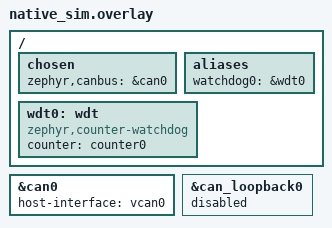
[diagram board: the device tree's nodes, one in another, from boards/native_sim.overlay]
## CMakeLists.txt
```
# Zephyr application: one codebase, two ECU roles (Kconfig choice APP_ROLE).
# Built as a freestanding application against the west workspace baked into the
# dev container (ZEPHYR_BASE).
cmake_minimum_required(VERSION 3.20.0)

# The dev image bakes firmware/west.yml into its west workspace at image build
# time, so an edited manifest changes nothing until the image is rebuilt. Make
# that mistake loud instead of silent.
if(DEFINED ENV{ZEPHYR_WORKSPACE} AND EXISTS "$ENV{ZEPHYR_WORKSPACE}/manifest/west.yml")
    file(READ "$ENV{ZEPHYR_WORKSPACE}/manifest/west.yml" baked_manifest)
    file(READ "${CMAKE_CURRENT_LIST_DIR}/../west.yml" repo_manifest)
    if(NOT baked_manifest STREQUAL repo_manifest)
        message(FATAL_ERROR
            "firmware/west.yml differs from the manifest baked into the dev image; "
            "rebuild the image with: tools/dev.sh --build")
    endif()
endif()

find_package(Zephyr REQUIRED HINTS $ENV{ZEPHYR_BASE})
project(can_ecu LANGUAGES C CXX)

target_sources(app PRIVATE
    src/main.cpp
    src/app/ecu.cpp
    src/app/test_control.cpp
    src/hal/can_bus.cpp
    src/hal/watchdog.cpp
    src/shell_cmds.c
    src/alloc_guard.c
)
target_sources_ifdef(CONFIG_APP_ROLE_SENSOR app PRIVATE src/app/sensor_role.cpp)
target_sources_ifdef(CONFIG_APP_ROLE_CONTROLLER app PRIVATE src/app/controller_role.cpp)

# No dynamic allocation after initialisation: route the public kernel and libc
# allocator entry points and the sys_heap leaf functions through
# src/alloc_guard.c, which panics once the application is up. The host C library
# is left alone on native_sim (the simulator runtime itself uses it). Symbols
# that are not compiled into the image are harmless to wrap (--gc-sections drops
# the unreferenced wrapper).
set(alloc_wrapped_symbols
    k_heap_alloc k_heap_aligned_alloc k_heap_calloc k_heap_realloc
    k_malloc k_calloc k_realloc k_aligned_alloc
    sys_heap_alloc sys_heap_aligned_alloc sys_heap_noalign_alloc sys_heap_realloc sys_heap_aligned_realloc)
if(NOT CONFIG_NATIVE_BUILD)
    list(APPEND alloc_wrapped_symbols malloc calloc realloc)
endif()
foreach(sym ${alloc_wrapped_symbols})
    zephyr_ld_options(-Wl,--wrap=${sym})
endforeach()

# Line coverage of the application under the system test suite (Phase 5):
# instrument only the application objects with gcov, not the kernel and the
# drivers (CONFIG_COVERAGE would instrument everything: 125 data files written
# at every exit, seconds on a bind-mounted checkout, and data lost whenever a
# test harness kills a process that is still writing). The flags are the ones
# Zephyr's own coverage support uses; libgcov reaches the final executable
# through the native simulator's link options, as with CONFIG_COVERAGE.
# Built by tools/build-ecu.sh native_sim <role> --coverage into build/<...>_cov/.
option(CAN_ECU_APP_COVERAGE "Instrument the application sources with gcov (native_sim only)" OFF)
if(CAN_ECU_APP_COVERAGE)
    if(NOT CONFIG_NATIVE_BUILD)
        message(FATAL_ERROR "CAN_ECU_APP_COVERAGE needs a native_sim build (the host's gcov)")
    endif()
    target_compile_options(app PRIVATE $<TARGET_PROPERTY:compiler,coverage>)
    target_link_options(native_simulator INTERFACE $<TARGET_PROPERTY:linker,coverage>)
endif()

# Platform-independent libraries (header-only): the generated protocol codec and
# the ECU state machines, both unit tested on the host (firmware/lib).
target_include_directories(app PRIVATE
    src
    ${CMAKE_CURRENT_SOURCE_DIR}/../lib/protocol/include
    ${CMAKE_CURRENT_SOURCE_DIR}/../lib/ecu_core/include
)
```

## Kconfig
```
# Application configuration. Select on the west command line, e.g.
#   west build -b native_sim -s firmware/app -- -DCONFIG_APP_ROLE_CONTROLLER=y
# or interactively with `west build -t menuconfig`.
mainmenu "can-ecu-sim firmware"

choice APP_ROLE
	prompt "ECU role"
	default APP_ROLE_SENSOR
	help
	  One codebase builds both nodes of the network. The role selects which
	  messages are published, which are monitored, and the node policy
	  (the controller has a safe state, the sensor only degrades).

config APP_ROLE_SENSOR
	bool "Sensor ECU: publishes SENSOR_DATA, BATTERY_STATUS and its heartbeat"

config APP_ROLE_CONTROLLER
	bool "Controller ECU: consumes sensor data, publishes CONTROLLER_COMMAND, has a safe state"

endchoice

config APP_TEST_HOOKS
	bool "Test-only hooks: accept TEST_CONTROL, simulate CAN controller error states"
	default y if BOARD_NATIVE_SIM
	default n
	help
	  Compiles in the TEST_CONTROL message handler and the HAL's simulated
	  CAN controller (ISO 11898-1 error counters) so error-passive and
	  bus-off can be exercised on a virtual bus that never produces
	  electrical errors. Off by default for hardware builds: a production
	  image must not expose fault injection on the bus.

menu "Timing"

config APP_SUPERVISOR_TICK_MS
	int "Supervisor period in ms"
	default 5
	help
	  Resolution of timeout detection, bus-off backoff timing and watchdog
	  feeding. Half the shortest message period keeps the detection latency
	  jitter below one sensor period.

config APP_SENSOR_DATA_TIMEOUT_MS
	int "SENSOR_DATA (10 ms) timeout in ms"
	default 35
	help
	  Three periods plus margin: two consecutive losses are tolerated, the
	  third is a timeout. The controller enters its safe state when it fires.

config APP_BATTERY_STATUS_TIMEOUT_MS
	int "BATTERY_STATUS (100 ms) timeout in ms"
	default 350

config APP_COMMAND_TIMEOUT_MS
	int "CONTROLLER_COMMAND (20 ms) timeout in ms"
	default 70

config APP_HEARTBEAT_TIMEOUT_MS
	int "Heartbeat (100 ms) timeout in ms"
	default 350

config APP_SAFE_STATE_RECOVERY_MS
	int "Inputs must be healthy this long before leaving the safe state"
	default 500

config APP_QUALITY_FAULT_THRESHOLD
	int "Consecutive rejected frames of one message that mark the node DEGRADED"
	default 3

endmenu

menu "CAN bus-off recovery"

config APP_BUSOFF_BACKOFF_INITIAL_MS
	int "Backoff before the first recovery attempt in ms"
	default 100

config APP_BUSOFF_BACKOFF_MAX_MS
	int "Backoff cap in ms (doubles per failed attempt)"
	default 1600

config APP_BUSOFF_RECOVERY_TIMEOUT_MS
	int "Time allowed for the controller to report error-active after recover()"
	default 500

config APP_BUSOFF_MAX_ATTEMPTS
	int "Consecutive failed attempts before the node latches FAULT"
	default 5

config APP_BUSOFF_STABLE_MS
	int "Error-active this long forgets previous attempts"
	default 10000

endmenu

menu "Watchdog and threads"

config APP_WATCHDOG_TIMEOUT_MS
	int "Hardware watchdog timeout in ms"
	default 1000

config APP_LIVENESS_WINDOW_MS
	int "Every thread must check in within this window or the watchdog is not fed"
	default 300

config APP_RX_QUEUE_DEPTH
	int "CAN receive queue depth (frames)"
	default 32
	help
	  Frames the driver can park while the RX thread is busy. A node never
	  receives its own frames, so 32 frames is about 270 ms of the
	  controller's nominal inbound traffic (120 frames/s) and 530 ms of the
	  sensor's (60 frames/s); against the whole bus (180 frames/s, what a
	  flood test can deliver to one node) it is about 180 ms. A frame that
	  finds the queue full is dropped in the HAL's receive callback and
	  counted (`dropped` in `ecu status`); the high-water mark is shown too.

config APP_THREAD_STACK_SIZE
	int "Stack size of the RX, TX and supervisor threads"
	default 2048

endmenu

source "Kconfig.zephyr"
```

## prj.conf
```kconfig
# --- Language -------------------------------------------------------------------
CONFIG_CPP=y
CONFIG_STD_CPP17=y
# Zephyr's minimal C++ library has no STL headers (<array>, <optional>, ...), so
# link the full libstdc++ (on the Nucleo this also selects picolibc as the C
# library). Only header-only facilities are used; exceptions and RTTI stay off
# (Zephyr default). The C/C++ runtime heap is closed per board, see boards/*.conf.
CONFIG_REQUIRES_FULL_LIBCPP=y

# --- No kernel heap: k_malloc is not even compiled with a zero-sized pool -----------
CONFIG_HEAP_MEM_POOL_SIZE=0

# --- Timing ---------------------------------------------------------------------
# Same tick rate on both targets. native_sim would otherwise default to 100 Hz,
# which rounds every relative timeout up to 10 ms steps.
CONFIG_SYS_CLOCK_TICKS_PER_SEC=10000

# --- CAN ------------------------------------------------------------------------
CONFIG_CAN=y
# Bus-off recovery is a decision of the application (backoff, attempt limit,
# FAULT state), not of the peripheral's automatic ABOM mode.
CONFIG_CAN_MANUAL_RECOVERY_MODE=y

# --- Watchdog -------------------------------------------------------------------
CONFIG_WATCHDOG=y
CONFIG_REBOOT=y

# --- Shell (diagnostics: `ecu status`, `ecu reset`) -------------------------------
CONFIG_SHELL=y
CONFIG_SHELL_PROMPT_UART="ecu:~$ "
CONFIG_SHELL_VT100_COLORS=n
CONFIG_SHELL_STACK_SIZE=3072
# Command history allocates from a k_heap on every command; the only run-time
# allocation in the image, so it is switched off (see src/alloc_guard.c).
CONFIG_SHELL_HISTORY=n
CONFIG_SHELL_WILDCARD=n

# --- Diagnostics ----------------------------------------------------------------
CONFIG_LOG=y
CONFIG_PRINTK=y
CONFIG_THREAD_NAME=y
CONFIG_MAIN_STACK_SIZE=2048
```

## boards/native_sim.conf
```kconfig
# Simulator only: process log messages synchronously in the caller's context so
# the output order matches execution exactly. Not used on hardware, where
# immediate mode would turn every log call into a multi-millisecond blocking UART
# write, including inside CAN RX callbacks.
CONFIG_LOG_MODE_IMMEDIATE=y

# Shell and log on the process's stdin/stdout instead of a pseudo terminal, so
# test scripts can drive the shell through a pipe.
CONFIG_UART_NATIVE_PTY_0_ON_STDINOUT=y

# Watchdog: a counter-based watchdog over the simulator's counter device
# (boards/native_sim.overlay), behind the same Zephyr API as the IWDG.
CONFIG_COUNTER=y
# Expiry must restart the process, not just end it: WDT_FLAG_RESET_SOC makes
# the counter watchdog call sys_arch_reboot(), which on native_sim exits and
# re-executes the same executable with the same arguments only when this option
# is set; without it Zephyr's weak default prints a warning and exits.
CONFIG_NATIVE_SIM_REBOOT=y
```

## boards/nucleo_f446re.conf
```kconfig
# picolibc would otherwise hand all remaining SRAM to malloc at boot
# (COMMON_LIBC_MALLOC_ARENA_SIZE=-1). With 0 there is no C/C++ runtime heap:
# malloc returns NULL, so a stray operator new cannot silently succeed.
CONFIG_COMMON_LIBC_MALLOC_ARENA_SIZE=0

# Cortex-M4F: use the hardware FPU for the sensor model and controller math.
# FPU_SHARING saves the FP registers on context switch (lazy stacking) because
# more than one thread uses floating point.
CONFIG_FPU=y
CONFIG_FPU_SHARING=y

# The STM32 IWDG driver otherwise installs CONFIG_IWDG_STM32_INITIAL_TIMEOUT
# (100 ms) and starts the IWDG at POST_KERNEL. The driver is single-channel and
# would reject the application's later wdt_install_timeout() with -ENOMEM, so
# app::start() would fail and the unfed 100 ms IWDG would reset the part
# forever. Keep the IWDG off until hal::Watchdog::init() arms it at
# CONFIG_APP_WATCHDOG_TIMEOUT_MS. (Board conf, not prj.conf: native_sim has no
# HAS_WDT_DISABLE_AT_BOOT and would reject the symbol.)
CONFIG_WDT_DISABLE_AT_BOOT=y
```

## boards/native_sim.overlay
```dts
/*
 * native_sim: route the Zephyr CAN API to a Linux SocketCAN interface instead of
 * the board's default in-process loopback controller. The interface name below
 * is the build-time default; it can be overridden per process at run time with
 *     ./zephyr.exe --can-if=vcan1
 * which is how the two ECU processes end up on different bus segments when the
 * fault-injection gateway sits between them.
 *
 * The watchdog is a counter-based software watchdog over the simulator's
 * counter device; the firmware reaches it through the same Zephyr watchdog API
 * as the STM32 IWDG (alias watchdog0 on both boards).
 */
/ {
	chosen {
		zephyr,canbus = &can0;
	};

	aliases {
		watchdog0 = &wdt0;
	};

	wdt0: wdt {
		compatible = "zephyr,counter-watchdog";
		counter = <&counter0>;
		status = "okay";
	};
};

&can0 {
	status = "okay";
	host-interface = "vcan0";
};

&can_loopback0 {
	status = "disabled";
};
```

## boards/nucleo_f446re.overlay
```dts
/*
 * Nucleo-F446RE: the board file already chooses bxCAN can2 (PB12/PB13) as
 * zephyr,canbus. Enable the independent watchdog: clocked by the LSI oscillator
 * (enabled in the board file) and impossible to stop once started, which is the
 * property the supervisor relies on.
 */
/ {
	aliases {
		watchdog0 = &iwdg;
	};
};

&iwdg {
	status = "okay";
};
```

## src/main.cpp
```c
// Entry point: bring up the application (HAL, queues, threads) and hand over.
// Zephyr ignores main()'s return value, so a failed start stops the system
// explicitly: on native_sim k_panic() exits the process with status 1, on
// Cortex-M it halts in the fatal-error handler where the watchdog, if it was
// already armed, resets the part.
#include <zephyr/kernel.h>
#include <zephyr/logging/log.h>
#include <zephyr/sys/util.h>

#include "app/ecu.hpp"

LOG_MODULE_REGISTER(main, LOG_LEVEL_INF);

int main()
{
    const int err = app::start();
    if (err != 0) {
        LOG_ERR("application start failed (%d)", err);
        k_panic();
        CODE_UNREACHABLE;
    }
    LOG_INF("%s ECU running", app::role::kName);
    return 0;
}
```

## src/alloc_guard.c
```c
/*
 * "No dynamic allocation after initialisation", enforced.
 *
 * The allocator entry points are wrapped at link time (-Wl,--wrap, see
 * CMakeLists.txt). Until alloc_guard_arm() is called at the end of application
 * start-up every call is forwarded to the real function; afterwards any call is
 * a fatal error. Together with tools/check-no-heap.sh (which lists every object
 * that references an allocator) this turns the design rule into something a
 * test can catch: a code path that allocates at run time panics the first time
 * it executes instead of working until memory fragments.
 *
 * Why the wrappers are needed although the heaps are "off":
 * CONFIG_HEAP_MEM_POOL_SIZE=0 compiles out only the system pool and its users
 * (k_malloc, k_calloc, k_aligned_alloc, k_realloc in kernel/mempool.c), and
 * CONFIG_COMMON_LIBC_MALLOC_ARENA_SIZE=0 makes malloc return NULL on the
 * Nucleo. The Zephyr heap API is unaffected by either: k_heap_alloc and
 * sys_heap_alloc allocate from whatever heap the caller passes, and a
 * subsystem's own K_HEAP_DEFINE'd heap (the shell's command history,
 * shell_history.c, disabled in prj.conf for exactly this reason) succeeds
 * normally. Wrapped here: the public kernel allocators, the k_heap API, the
 * sys_heap leaf functions they all end in, and on the Nucleo the C allocators
 * (which libstdc++'s operator new calls). The host C library is not wrapped on
 * native_sim: it belongs to the simulator runtime, so there an application
 * malloc is caught only by the static scan.
 *
 * Functions that are not compiled into the image (k_malloc with a zero pool)
 * are harmless to wrap: nothing references their __wrap_ and the linker's
 * --gc-sections drops the wrapper with its __real_ reference.
 */
#include <zephyr/kernel.h>
#include <zephyr/logging/log.h>
#include <zephyr/sys/sys_heap.h>

#include <stddef.h>

LOG_MODULE_REGISTER(alloc_guard, LOG_LEVEL_ERR);

static bool armed;

void alloc_guard_arm(void)
{
	armed = true;
}

bool alloc_guard_armed(void)
{
	return armed;
}

static void trap(const char *what)
{
	LOG_ERR("dynamic allocation after init: %s", what);
	k_panic();
}

#define GUARDED(ret, name, params, args)                                                          \
	ret __real_##name params;                                                                 \
	ret __wrap_##name params                                                                  \
	{                                                                                         \
		if (armed) {                                                                      \
			trap(#name);                                                              \
		}                                                                                 \
		return __real_##name args;                                                        \
	}

/* --- Zephyr kernel heap API --- */
GUARDED(void *, k_heap_alloc, (struct k_heap *h, size_t bytes, k_timeout_t timeout), (h, bytes, timeout))
GUARDED(void *, k_heap_aligned_alloc, (struct k_heap *h, size_t align, size_t bytes, k_timeout_t timeout),
	(h, align, bytes, timeout))
GUARDED(void *, k_heap_calloc, (struct k_heap *h, size_t num, size_t size, k_timeout_t timeout),
	(h, num, size, timeout))
GUARDED(void *, k_heap_realloc, (struct k_heap *h, void *ptr, size_t bytes, k_timeout_t timeout),
	(h, ptr, bytes, timeout))
GUARDED(void *, k_malloc, (size_t size), (size))
GUARDED(void *, k_calloc, (size_t nmemb, size_t size), (nmemb, size))
GUARDED(void *, k_realloc, (void *ptr, size_t size), (ptr, size))
GUARDED(void *, k_aligned_alloc, (size_t align, size_t size), (align, size))

/* --- sys_heap leaf functions --- */
GUARDED(void *, sys_heap_alloc, (struct sys_heap *heap, size_t bytes), (heap, bytes))
GUARDED(void *, sys_heap_aligned_alloc, (struct sys_heap *heap, size_t align, size_t bytes),
	(heap, align, bytes))
GUARDED(void *, sys_heap_noalign_alloc, (struct sys_heap *heap, size_t align, size_t bytes),
	(heap, align, bytes))
GUARDED(void *, sys_heap_realloc, (struct sys_heap *heap, void *ptr, size_t bytes), (heap, ptr, bytes))
GUARDED(void *, sys_heap_aligned_realloc, (struct sys_heap *heap, void *ptr, size_t align, size_t bytes),
	(heap, ptr, align, bytes))

#ifndef CONFIG_NATIVE_BUILD
/* --- C library (picolibc on the Nucleo; the host libc is not wrapped) --- */
GUARDED(void *, malloc, (size_t size), (size))
GUARDED(void *, calloc, (size_t n, size_t size), (n, size))
GUARDED(void *, realloc, (void *p, size_t size), (p, size))
#endif
```

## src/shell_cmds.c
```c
/*
 * Shell commands: `ecu status` prints the node, CAN, traffic and watchdog state
 * with every error counter; `ecu reset` clears latched faults and, with test
 * hooks, pending test faults. Written in C
 * because Zephyr's shell macros rely on C designated initialisers; the data
 * comes from the C++ application through app/status.h.
 */
#include <zephyr/shell/shell.h>

#include <inttypes.h>

#include "app/status.h"

static int cmd_status(const struct shell *sh, size_t argc, char **argv)
{
	ARG_UNUSED(argc);
	ARG_UNUSED(argv);
	static struct ecu_status s; /* static: too large for the shell thread's stack */

	ecu_status_get(&s);

	shell_print(sh, "role=%s test_hooks=%d uptime_ms=%" PRId64, s.role, s.test_hooks, s.uptime_ms);
	shell_print(sh, "node: state=%s reason=\"%s\" since_ms=%" PRId64 " safe_state_entries=%" PRIu32
		    " error_flags=0x%02x",
		    s.node_state, s.node_reason, s.node_state_age_ms, s.safe_state_entries, s.error_flags);
	shell_print(sh, "can: phase=%s state=%s tec=%u rec=%u manual_recovery=%d simulated=%d",
		    s.can_phase, s.can_state, s.tec, s.rec, s.manual_recovery, s.simulation_active);
	shell_print(sh, "can: bus_off=%" PRIu32 " passive=%" PRIu32 " recovery_attempts=%" PRIu32
		    " recoveries_ok=%" PRIu32 " recovery_failures=%" PRIu32 " last_recovery_ms=%" PRId64
		    " backoff_ms=%" PRIu32,
		    s.bus_off_events, s.passive_events, s.recovery_attempts, s.recoveries_ok,
		    s.recovery_failures, s.last_recovery_duration_ms, s.current_backoff_ms);
	shell_print(sh, "tx: sent=%" PRIu32 " ok=%" PRIu32 " err=%" PRIu32 " busy=%" PRIu32 " rejected=%" PRIu32
		    " blocked_bus_off=%" PRIu32 " tick_overruns=%" PRIu32,
		    s.tx_sent, s.tx_completed_ok, s.tx_completed_error, s.tx_busy, s.tx_rejected,
		    s.tx_blocked_bus_off, s.tx_tick_overruns);
	shell_print(sh, "rx: frames=%" PRIu32 " unknown=%" PRIu32 " queue_hwm=%" PRIu32 "/%" PRIu32
		    " dropped=%" PRIu32 " events_dropped=%" PRIu32 " echo_responses=%" PRIu32
		    " test_commands=%" PRIu32,
		    s.rx_frames, s.rx_unknown, s.rx_queue_hwm, s.rx_queue_depth, s.rx_dropped,
		    s.can_events_dropped, s.echo_responses, s.test_commands);
	for (size_t i = 0; i < s.rx_count; ++i) {
		const struct ecu_rx_status *r = &s.rx[i];

		shell_print(sh, "rx %s: alive=%d age_ms=%" PRId64 " ok=%" PRIu32 " crc=%" PRIu32 " counter=%" PRIu32
			    " dlc=%" PRIu32 " skipped=%" PRIu32 " lost=%" PRIu32 " timeouts=%" PRIu32,
			    r->name, r->alive, r->age_ms, r->accepted, r->crc_faults, r->counter_faults,
			    r->dlc_faults, r->skipped, r->lost_frames, r->timeouts);
	}
	shell_print(sh, "wdt: available=%d timeout_ms=%" PRIu32 " feeds=%" PRIu32 " skipped=%" PRIu32
		    " stale_threads=0x%" PRIx32,
		    s.wdt_available, s.wdt_timeout_ms, s.wdt_feeds, s.wdt_skipped, s.liveness_stale_mask);
	if (s.test_hooks) {
		shell_print(sh, "hooks: suppressed=%" PRIu32 " corrupted=%" PRIu32 " skipped=%" PRIu32
			    " frozen=%" PRIu32,
			    s.hook_suppressed, s.hook_corrupted, s.hook_skipped, s.hook_frozen);
	}
	shell_print(sh, "%s: %s", s.role, s.role_detail);
	return 0;
}

static int cmd_reset(const struct shell *sh, size_t argc, char **argv)
{
	ARG_UNUSED(argc);
	ARG_UNUSED(argv);
	ecu_reset_faults();
	shell_print(sh, "faults cleared: FAULT state, CAN recovery backoff, error_flags, watchdog skip count, "
		    "per-message rx fault counters%s (cumulative tx/rx/bus-off counters kept)",
		    IS_ENABLED(CONFIG_APP_TEST_HOOKS) ? ", pending test faults and hook counters" : "");
	return 0;
}

/* NOLINTBEGIN(bugprone-branch-clone): inside Zephyr's SHELL_CMD/SHELL_CMD_REGISTER expansions */
SHELL_STATIC_SUBCMD_SET_CREATE(sub_ecu,
	SHELL_CMD(status, NULL, "Node, CAN, traffic and watchdog status with error counters", cmd_status),
	SHELL_CMD(reset, NULL,
		  "Clear latched faults (FAULT state, exhausted CAN recovery), error_flags, per-message "
		  "RX fault counters and, with test hooks, pending test faults and hook counters",
		  cmd_reset),
	SHELL_SUBCMD_SET_END);

SHELL_CMD_REGISTER(ecu, &sub_ecu, "ECU diagnostics", NULL);
/* NOLINTEND(bugprone-branch-clone) */
```
